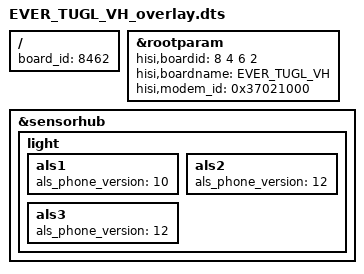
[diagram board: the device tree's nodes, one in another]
/**
 * Copyright (C) 2014 Hisilicon Ltd.
 *
 *  This program is free software; you can redistribute it and/or modify
 *  it under the terms of the GNU General Public License version 2 as
 *  publishhed by the Free Software Foundation.
 */

/dts-v1/;
/plugin/;

/include/ "EVER_TUGL_VG_overlay.dtsi"
/include/ "EVER_TUGL_VH_pin.dtsi"
/include/ "EVER_TUGL_VH_modem_pin.dtsi"

/ {
    board_id = <8462>;
};
	&rootparam{
		hisi,boardid = <8 4 6 2>;
		hisi,boardname = "EVER_TUGL_VH";
		hisi,modem_id = <0x37021000>;
	};

	&sensorhub{
		light{
			als1{
				als_phone_version = <10>;
			};
			als2{
				als_phone_version = <12>;
			};
			als3{
				als_phone_version = <12>;
			};
		};
    };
